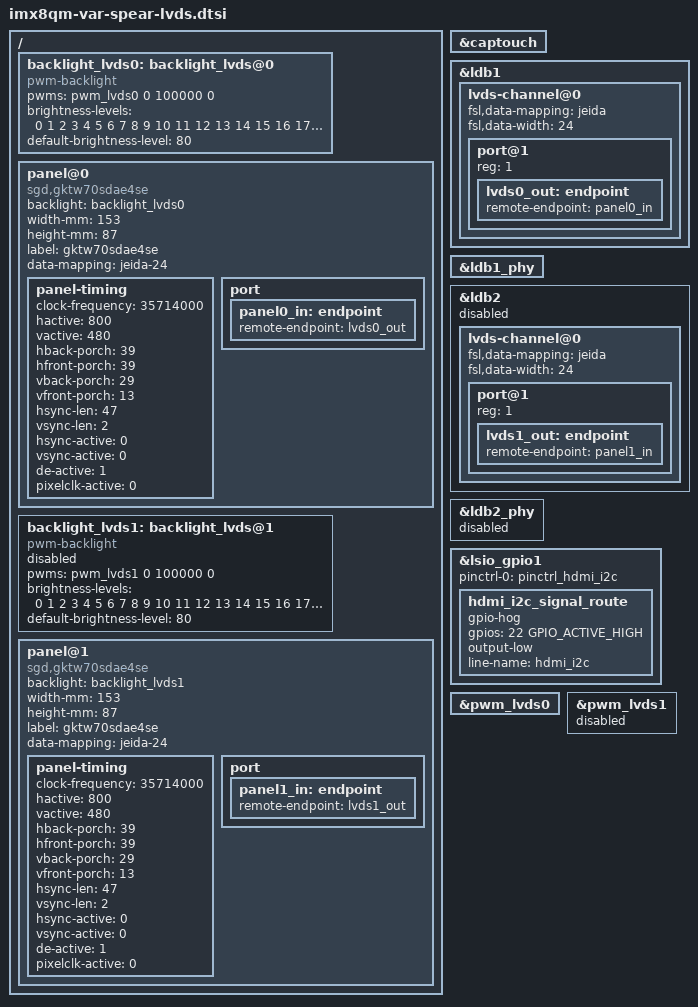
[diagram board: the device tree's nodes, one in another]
/*
 * Copyright 2019 Variscite Ltd.
 *
 * This program is free software; you can redistribute it and/or
 * modify it under the terms of the GNU General Public License
 * as published by the Free Software Foundation; either version 2
 * of the License, or (at your option) any later version.
 *
 * This program is distributed in the hope that it will be useful,
 * but WITHOUT ANY WARRANTY; without even the implied warranty of
 * MERCHANTABILITY or FITNESS FOR A PARTICULAR PURPOSE.  See the
 * GNU General Public License for more details.
 */

/ {
	backlight_lvds0: backlight_lvds@0 {
		compatible = "pwm-backlight";
		pwms = <&pwm_lvds0 0 100000 0>;
		brightness-levels = < 0  1  2  3  4  5  6  7  8  9
				     10 11 12 13 14 15 16 17 18 19
				     20 21 22 23 24 25 26 27 28 29
				     30 31 32 33 34 35 36 37 38 39
				     40 41 42 43 44 45 46 47 48 49
				     50 51 52 53 54 55 56 57 58 59
				     60 61 62 63 64 65 66 67 68 69
				     70 71 72 73 74 75 76 77 78 79
				     80 81 82 83 84 85 86 87 88 89
				     90 91 92 93 94 95 96 97 98 99
				    100>;
		default-brightness-level = <80>;
		status = "okay";
	};

	panel@0 {
		compatible = "sgd,gktw70sdae4se", "panel-lvds";
		backlight = <&backlight_lvds0>;
		width-mm = <153>;
		height-mm = <87>;
		label = "gktw70sdae4se";
		data-mapping = "jeida-24";
		status = "okay";

		panel-timing {
			clock-frequency = <35714000>;
			hactive = <800>;
			vactive = <480>;
			hback-porch = <39>;
			hfront-porch = <39>;
			vback-porch = <29>;
			vfront-porch = <13>;
			hsync-len = <47>;
			vsync-len = <2>;
			hsync-active = <0>;
			vsync-active = <0>;
			de-active = <1>;
			pixelclk-active = <0>;
		};

		port {
			panel0_in: endpoint {
				remote-endpoint = <&lvds0_out>;
			};
		};
	};

	backlight_lvds1: backlight_lvds@1 {
		compatible = "pwm-backlight";
		pwms = <&pwm_lvds1 0 100000 0>;
		brightness-levels = < 0  1  2  3  4  5  6  7  8  9
				     10 11 12 13 14 15 16 17 18 19
				     20 21 22 23 24 25 26 27 28 29
				     30 31 32 33 34 35 36 37 38 39
				     40 41 42 43 44 45 46 47 48 49
				     50 51 52 53 54 55 56 57 58 59
				     60 61 62 63 64 65 66 67 68 69
				     70 71 72 73 74 75 76 77 78 79
				     80 81 82 83 84 85 86 87 88 89
				     90 91 92 93 94 95 96 97 98 99
				    100>;
		default-brightness-level = <80>;
		status = "disabled";
	};


	panel@1 {
		compatible = "sgd,gktw70sdae4se", "panel-lvds";
		backlight = <&backlight_lvds1>;
		width-mm = <153>;
		height-mm = <87>;
		label = "gktw70sdae4se";
		data-mapping = "jeida-24";
		status = "okay";

		panel-timing {
			clock-frequency = <35714000>;
			hactive = <800>;
			vactive = <480>;
			hback-porch = <39>;
			hfront-porch = <39>;
			vback-porch = <29>;
			vfront-porch = <13>;
			hsync-len = <47>;
			vsync-len = <2>;
			hsync-active = <0>;
			vsync-active = <0>;
			de-active = <1>;
			pixelclk-active = <0>;
		};

		port {
			panel1_in: endpoint {
				remote-endpoint = <&lvds1_out>;
			};
		};
	};
};

&captouch {
	status = "okay";
};

&ldb1 {
	status = "okay";

	lvds-channel@0 {
		fsl,data-mapping = "jeida";
		fsl,data-width = <24>;
		status = "okay";

		port@1 {
			reg = <1>;

			lvds0_out: endpoint {
				remote-endpoint = <&panel0_in>;
			};
		};
	};
};

&ldb1_phy {
	status = "okay";
};

&ldb2 {
	status = "disabled";

	lvds-channel@0 {
		fsl,data-mapping = "jeida";
		fsl,data-width = <24>;
		status = "okay";

		port@1 {
			reg = <1>;

			lvds1_out: endpoint {
				remote-endpoint = <&panel1_in>;
			};
		};
	};
};

&ldb2_phy {
	status = "disabled";
};

&lsio_gpio1 {
        pinctrl-names = "default";
        pinctrl-0 = <&pinctrl_hdmi_i2c>;

        hdmi_i2c_signal_route {
                gpio-hog;
                gpios = <22 GPIO_ACTIVE_HIGH>;
                output-low;
                line-name = "hdmi_i2c";
        };
};

&pwm_lvds0 {
        status = "okay";
};

&pwm_lvds1 {
        status = "disabled";
};
